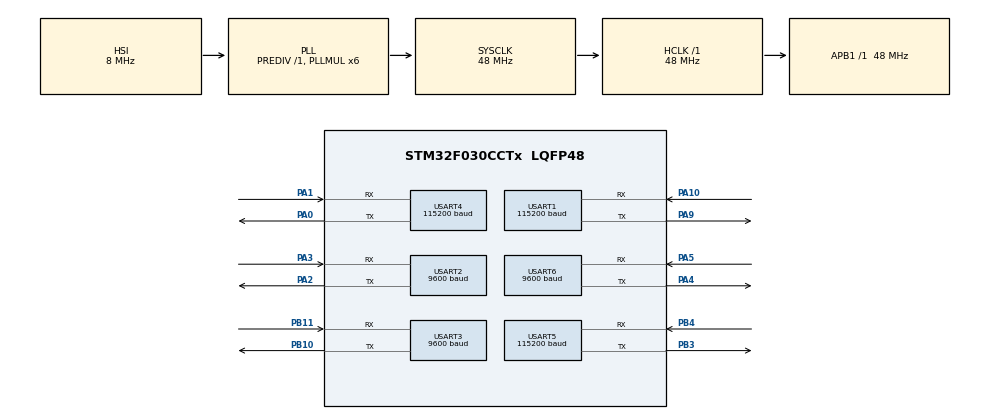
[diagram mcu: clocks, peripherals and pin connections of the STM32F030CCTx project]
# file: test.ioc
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Dma.Request0=USART1_RX
Dma.Request1=USART5_RX
Dma.Request2=USART4_RX
Dma.USART1_RX.0.Direction=DMA_PERIPH_TO_MEMORY
Dma.USART1_RX.0.Instance=DMA1_Channel1
Dma.USART1_RX.0.MemDataAlignment=DMA_MDATAALIGN_BYTE
Dma.USART1_RX.0.MemInc=DMA_MINC_ENABLE
Dma.USART1_RX.0.Mode=DMA_NORMAL
Dma.USART1_RX.0.PeriphDataAlignment=DMA_PDATAALIGN_BYTE
Dma.USART1_RX.0.PeriphInc=DMA_PINC_DISABLE
Dma.USART1_RX.0.Priority=DMA_PRIORITY_MEDIUM
Dma.USART4_RX.2.Direction=DMA_PERIPH_TO_MEMORY
Dma.USART4_RX.2.Instance=DMA1_Channel5
Dma.USART4_RX.2.MemDataAlignment=DMA_MDATAALIGN_BYTE
Dma.USART4_RX.2.MemInc=DMA_MINC_ENABLE
Dma.USART4_RX.2.Mode=DMA_NORMAL
Dma.USART4_RX.2.PeriphDataAlignment=DMA_PDATAALIGN_BYTE
Dma.USART4_RX.2.PeriphInc=DMA_PINC_DISABLE
Dma.USART4_RX.2.Priority=DMA_PRIORITY_HIGH
Dma.USART5_RX.1.Direction=DMA_PERIPH_TO_MEMORY
Dma.USART5_RX.1.Instance=DMA1_Channel3
Dma.USART5_RX.1.MemDataAlignment=DMA_MDATAALIGN_BYTE
Dma.USART5_RX.1.MemInc=DMA_MINC_ENABLE
Dma.USART5_RX.1.Mode=DMA_NORMAL
Dma.USART5_RX.1.PeriphDataAlignment=DMA_PDATAALIGN_BYTE
Dma.USART5_RX.1.PeriphInc=DMA_PINC_DISABLE
Dma.USART5_RX.1.Priority=DMA_PRIORITY_MEDIUM
Mcu.Family=STM32F0
Mcu.Name=STM32F030CCTx
Mcu.Package=LQFP48
NVIC.DMA1_Channel1_IRQn=true\:0\:0\:false\:false\:true\:false\:true\:true
NVIC.DMA1_Channel2_3_IRQn=true\:0\:0\:false\:false\:true\:false\:true\:true
NVIC.DMA1_Channel4_5_IRQn=true\:0\:0\:false\:false\:true\:false\:true\:true
NVIC.USART1_IRQn=true\:0\:0\:false\:false\:true\:true\:true\:true
NVIC.USART3_6_IRQn=true\:0\:0\:false\:false\:true\:true\:true\:true
PA0.Mode=Asynchronous
PA0.Signal=USART4_TX
PA1.Mode=Asynchronous
PA1.Signal=USART4_RX
PA10.Mode=Asynchronous
PA10.Signal=USART1_RX
PA2.Mode=Asynchronous
PA2.Signal=USART2_TX
PA3.Mode=Asynchronous
PA3.Signal=USART2_RX
PA4.Mode=Asynchronous
PA4.Signal=USART6_TX
PA5.Mode=Asynchronous
PA5.Signal=USART6_RX
PA9.Mode=Asynchronous
PA9.Signal=USART1_TX
PB10.Mode=Asynchronous
PB10.Signal=USART3_TX
PB11.Mode=Asynchronous
PB11.Signal=USART3_RX
PB3.Mode=Asynchronous
PB3.Signal=USART5_TX
PB4.Mode=Asynchronous
PB4.Signal=USART5_RX
PF0-OSC_IN.Mode=HSE-External-Oscillator
PF0-OSC_IN.Signal=RCC_OSC_IN
PF1-OSC_OUT.Mode=HSE-External-Oscillator
PF1-OSC_OUT.Signal=RCC_OSC_OUT
ProjectManager.HeapSize=0x200
ProjectManager.StackSize=0x400
ProjectManager.TargetToolchain=STM32CubeIDE
RCC.AHBFreq_Value=48000000
RCC.APB1Freq_Value=48000000
RCC.APB1TimFreq_Value=48000000
RCC.HCLKFreq_Value=48000000
RCC.PLLMUL=RCC_PLL_MUL6
RCC.SYSCLKFreq_VALUE=48000000
RCC.SYSCLKSource=RCC_SYSCLKSOURCE_PLLCLK
USART1.BaudRate=115200
USART1.VirtualMode-Asynchronous=VM_ASYNC
USART2.BaudRate=9600
USART2.VirtualMode-Asynchronous=VM_ASYNC
USART3.BaudRate=9600
USART3.VirtualMode-Asynchronous=VM_ASYNC
USART4.BaudRate=115200
USART4.VirtualMode-Asynchronous=VM_ASYNC
USART5.BaudRate=115200
USART5.VirtualMode-Asynchronous=VM_ASYNC
USART6.BaudRate=9600
USART6.VirtualMode=VM_ASYNC
board=custom

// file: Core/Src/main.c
/* USER CODE BEGIN Header */
/**
  ******************************************************************************
  * @file           : main.c
  * @brief          : Main program body
  ******************************************************************************
  * @attention
  *
  * Copyright (c) 2025 STMicroelectronics.
  * All rights reserved.
  *
  * This software is licensed under terms that can be found in the LICENSE file
  * in the root directory of this software component.
  * If no LICENSE file comes with this software, it is provided AS-IS.
  *
  ******************************************************************************
  */
/* USER CODE END Header */
#include "main.h"
#include "string.h"

/* USER CODE BEGIN PD */
#define MAX_PACKETS     30
#define MAX_PACKET_SIZE 200
/* USER CODE END PD */

UART_HandleTypeDef huart1;
UART_HandleTypeDef huart2;
UART_HandleTypeDef huart3;
UART_HandleTypeDef huart4;
UART_HandleTypeDef huart5;
UART_HandleTypeDef huart6;
DMA_HandleTypeDef hdma_usart1_rx;
DMA_HandleTypeDef hdma_usart4_rx;
DMA_HandleTypeDef hdma_usart5_rx;

uint8_t UART1_RxBuffer[100] = {0}; //UART1: HMI
uint8_t UART5_RxBuffer[100] = {0}; //UART5: Robot
uint8_t UART4_RxBuffer[2000] = {0}; //UART4: Laser Controller
uint8_t buffer[1000] = {0};
uint8_t transfer[100] = {0};
uint8_t uart4_packets[MAX_PACKETS][MAX_PACKET_SIZE];  // Store extracted packets
uint16_t uart4_packet_sizes[MAX_PACKETS];      // Store actual sizes
uint8_t prt[10] = {0};
uint8_t p = 0;
uint8_t pno[1] = {0};
uint16_t RxDataLen = 0;
void SystemClock_Config(void);
static void MX_GPIO_Init(void);
static void MX_DMA_Init(void);
static void MX_USART1_UART_Init(void);
static void MX_USART2_UART_Init(void);
static void MX_USART3_UART_Init(void);
static void MX_USART4_UART_Init(void);
static void MX_USART5_UART_Init(void);
static void MX_USART6_UART_Init(void);

int main(void)
{

  /* MCU Configuration--------------------------------------------------------*/

  /* Reset of all peripherals, Initializes the Flash interface and the Systick. */
  HAL_Init();

  /* Configure the system clock */
  SystemClock_Config();

  /* Initialize all configured peripherals */
  MX_GPIO_Init();
  MX_DMA_Init();
  MX_USART1_UART_Init();
  MX_USART2_UART_Init();
  MX_USART3_UART_Init();
  MX_USART4_UART_Init();
  MX_USART5_UART_Init();
  MX_USART6_UART_Init();
  /* USER CODE BEGIN 2 */

  HAL_UARTEx_ReceiveToIdle_DMA(&huart1, UART1_RxBuffer, 100); //Read from HMI
  __HAL_DMA_DISABLE_IT(&hdma_usart1_rx, DMA_IT_HT);
  HAL_UARTEx_ReceiveToIdle_DMA(&huart5, UART5_RxBuffer, 100); //Read from Robot
  __HAL_DMA_DISABLE_IT(&hdma_usart5_rx, DMA_IT_HT);
  HAL_UARTEx_ReceiveToIdle_DMA(&huart4, UART4_RxBuffer, 1000); //Read from Laser Controller
  __HAL_DMA_DISABLE_IT(&hdma_usart4_rx, DMA_IT_HT);
  /* USER CODE END 2 */

  /* Infinite loop */
  while (1)
  {
	  if (buffer[0] != 0 )
	 	  {
	 		  memcpy(transfer, buffer, 100);
	 		  memmove(buffer, &buffer[100], 900);
	 		  memset(&buffer[900], 0, 100);
	 		  pno[0] = prt[0];
	 		  memmove(prt, &prt[1],9);
	 		  HAL_UART_Transmit(&huart4, transfer, RxDataLen, 500);
	 		  //HAL_Delay(500);
	 	  }
    /* USER CODE BEGIN 3 */
  }
  //memset(UART1_RxBuffer, 0, 32);

  /* USER CODE END 3 */
}

void extract_uart4_packets(uint8_t *buf, uint16_t len) {
    int pkt_idx = 0;

    for (int i = 0; i < len - 1 && pkt_idx < MAX_PACKETS; ) {
        // Look for start marker
        if (buf[i] == 0x5A && buf[i + 1] == 0xA5) {
            int start = i;
            int end = -1;

            // Find next 0x5A 0xA5 (start of next packet)
            for (int j = i + 2; j < len - 1; j++) {
                if (buf[j] == 0x5A && buf[j + 1] == 0xA5) {
                    end = j;
                    break;
                }
            }

            if (end == -1) {
                // No more headers → rest is last packet
                end = len;
            }

            int pkt_len = end - start;
            if (pkt_len > 0 && pkt_len <= MAX_PACKET_SIZE) {
                memcpy(uart4_packets[pkt_idx], &buf[start], pkt_len);
                uart4_packet_sizes[pkt_idx] = pkt_len;
                pkt_idx++;
            }

            i = end; // Continue from next header or end
        } else {
            i++; // Not a packet start, scan forward
        }
    }

    // Clear unused sizes
    for (int j = pkt_idx; j < MAX_PACKETS; j++) {
        uart4_packet_sizes[j] = 0;
    }
}

void HAL_UARTEx_RxEventCallback(UART_HandleTypeDef *huart, uint16_t Size)
{
	if (huart->Instance == USART1)
	{
		RxDataLen = Size;
		uint8_t i;
		p = 1;
		//HAL_UART_Transmit(&huart4, UART1_RxBuffer, RxDataLen, 500);
		for (i = 0; i<10; i++)
		{
			if (buffer[i*100] == 0) {
				memcpy(&buffer[i*100], UART1_RxBuffer, 100);
				//break;
			}
			if (prt[i] == 0){
				prt[i] = p;
				break;
			}
		}
		HAL_UARTEx_ReceiveToIdle_DMA(&huart1, UART1_RxBuffer, 100);
		__HAL_DMA_DISABLE_IT(&hdma_usart1_rx, DMA_IT_HT);
	}

	else if (huart->Instance == USART5)
	{
		RxDataLen = Size;
		uint8_t i;
		p = 5;
		//HAL_UART_Transmit(&huart4, rx5_data, RxDataLen, 100);
		for (i = 0; i<10; i++)
		{
			if (buffer[i*100] == 0) {
				memcpy(&buffer[i*100], UART5_RxBuffer, 100);
				//break;
			}
			if (prt[i] == 0){
				prt[i] = p;
				break;
			}
		}
		HAL_UARTEx_ReceiveToIdle_DMA(&huart5, UART5_RxBuffer, 100);
		__HAL_DMA_DISABLE_IT(&hdma_usart5_rx, DMA_IT_HT);
	}

	else if (huart->Instance == USART4)
	{
		RxDataLen = Size;
		extract_uart4_packets(UART4_RxBuffer, Size);
		for (int i = 0; i < MAX_PACKETS && uart4_packet_sizes[i] > 0; i++)
		{
			if (pno[0] == 1){
				HAL_UART_Transmit(&huart1, uart4_packets[i], uart4_packet_sizes[i], 100);
			}
			else if (pno[0] == 5){
				HAL_UART_Transmit(&huart5, uart4_packets[i], uart4_packet_sizes[i], 100);
			}
			else if (pno[0] == 0){
				HAL_UART_Transmit(&huart5, uart4_packets[i], uart4_packet_sizes[i], 100);
			}
		}
		HAL_UARTEx_ReceiveToIdle_DMA(&huart4, UART4_RxBuffer, 1000);
		__HAL_DMA_DISABLE_IT(&hdma_usart4_rx, DMA_IT_HT);
	}
}

void SystemClock_Config(void)
{
  RCC_OscInitTypeDef RCC_OscInitStruct = {0};
  RCC_ClkInitTypeDef RCC_ClkInitStruct = {0};
  RCC_PeriphCLKInitTypeDef PeriphClkInit = {0};

  /** Initializes the RCC Oscillators according to the specified parameters
  * in the RCC_OscInitTypeDef structure.
  */
  RCC_OscInitStruct.OscillatorType = RCC_OSCILLATORTYPE_HSI;
  RCC_OscInitStruct.HSIState = RCC_HSI_ON;
  RCC_OscInitStruct.HSICalibrationValue = RCC_HSICALIBRATION_DEFAULT;
  RCC_OscInitStruct.PLL.PLLState = RCC_PLL_ON;
  RCC_OscInitStruct.PLL.PLLSource = RCC_PLLSOURCE_HSI;
  RCC_OscInitStruct.PLL.PLLMUL = RCC_PLL_MUL6;
  RCC_OscInitStruct.PLL.PREDIV = RCC_PREDIV_DIV1;
  if (HAL_RCC_OscConfig(&RCC_OscInitStruct) != HAL_OK)
  {
    Error_Handler();
  }

  /** Initializes the CPU, AHB and APB buses clocks
  */
  RCC_ClkInitStruct.ClockType = RCC_CLOCKTYPE_HCLK|RCC_CLOCKTYPE_SYSCLK
                              |RCC_CLOCKTYPE_PCLK1;
  RCC_ClkInitStruct.SYSCLKSource = RCC_SYSCLKSOURCE_PLLCLK;
  RCC_ClkInitStruct.AHBCLKDivider = RCC_SYSCLK_DIV1;
  RCC_ClkInitStruct.APB1CLKDivider = RCC_HCLK_DIV1;

  if (HAL_RCC_ClockConfig(&RCC_ClkInitStruct, FLASH_LATENCY_1) != HAL_OK)
  {
    Error_Handler();
  }
  PeriphClkInit.PeriphClockSelection = RCC_PERIPHCLK_USART1;
  PeriphClkInit.Usart1ClockSelection = RCC_USART1CLKSOURCE_PCLK1;
  if (HAL_RCCEx_PeriphCLKConfig(&PeriphClkInit) != HAL_OK)
  {
    Error_Handler();
  }
}

static void MX_USART1_UART_Init(void)
{

  huart1.Instance = USART1;
  huart1.Init.BaudRate = 115200;
  huart1.Init.WordLength = UART_WORDLENGTH_8B;
  huart1.Init.StopBits = UART_STOPBITS_1;
  huart1.Init.Parity = UART_PARITY_NONE;
  huart1.Init.Mode = UART_MODE_TX_RX;
  huart1.Init.HwFlowCtl = UART_HWCONTROL_NONE;
  huart1.Init.OverSampling = UART_OVERSAMPLING_16;
  huart1.Init.OneBitSampling = UART_ONE_BIT_SAMPLE_DISABLE;
  huart1.AdvancedInit.AdvFeatureInit = UART_ADVFEATURE_NO_INIT;
  if (HAL_UART_Init(&huart1) != HAL_OK)
  {
    Error_Handler();
  }

}

static void MX_USART2_UART_Init(void)
{

  huart2.Instance = USART2;
  huart2.Init.BaudRate = 9600;
  huart2.Init.WordLength = UART_WORDLENGTH_8B;
  huart2.Init.StopBits = UART_STOPBITS_1;
  huart2.Init.Parity = UART_PARITY_NONE;
  huart2.Init.Mode = UART_MODE_TX_RX;
  huart2.Init.HwFlowCtl = UART_HWCONTROL_NONE;
  huart2.Init.OverSampling = UART_OVERSAMPLING_16;
  huart2.Init.OneBitSampling = UART_ONE_BIT_SAMPLE_DISABLE;
  huart2.AdvancedInit.AdvFeatureInit = UART_ADVFEATURE_NO_INIT;
  if (HAL_UART_Init(&huart2) != HAL_OK)
  {
    Error_Handler();
  }

}

static void MX_USART3_UART_Init(void)
{

  huart3.Instance = USART3;
  huart3.Init.BaudRate = 9600;
  huart3.Init.WordLength = UART_WORDLENGTH_8B;
  huart3.Init.StopBits = UART_STOPBITS_1;
  huart3.Init.Parity = UART_PARITY_NONE;
  huart3.Init.Mode = UART_MODE_TX_RX;
  huart3.Init.HwFlowCtl = UART_HWCONTROL_NONE;
  huart3.Init.OverSampling = UART_OVERSAMPLING_16;
  huart3.Init.OneBitSampling = UART_ONE_BIT_SAMPLE_DISABLE;
  huart3.AdvancedInit.AdvFeatureInit = UART_ADVFEATURE_NO_INIT;
  if (HAL_UART_Init(&huart3) != HAL_OK)
  {
    Error_Handler();
  }

}

static void MX_USART4_UART_Init(void)
{

  huart4.Instance = USART4;
  huart4.Init.BaudRate = 115200;
  huart4.Init.WordLength = UART_WORDLENGTH_8B;
  huart4.Init.StopBits = UART_STOPBITS_1;
  huart4.Init.Parity = UART_PARITY_NONE;
  huart4.Init.Mode = UART_MODE_TX_RX;
  huart4.Init.HwFlowCtl = UART_HWCONTROL_NONE;
  huart4.Init.OverSampling = UART_OVERSAMPLING_16;
  huart4.Init.OneBitSampling = UART_ONE_BIT_SAMPLE_DISABLE;
  huart4.AdvancedInit.AdvFeatureInit = UART_ADVFEATURE_NO_INIT;
  if (HAL_UART_Init(&huart4) != HAL_OK)
  {
    Error_Handler();
  }

}

static void MX_USART5_UART_Init(void)
{

  huart5.Instance = USART5;
  huart5.Init.BaudRate = 115200;
  huart5.Init.WordLength = UART_WORDLENGTH_8B;
  huart5.Init.StopBits = UART_STOPBITS_1;
  huart5.Init.Parity = UART_PARITY_NONE;
  huart5.Init.Mode = UART_MODE_TX_RX;
  huart5.Init.HwFlowCtl = UART_HWCONTROL_NONE;
  huart5.Init.OverSampling = UART_OVERSAMPLING_16;
  huart5.Init.OneBitSampling = UART_ONE_BIT_SAMPLE_DISABLE;
  huart5.AdvancedInit.AdvFeatureInit = UART_ADVFEATURE_NO_INIT;
  if (HAL_UART_Init(&huart5) != HAL_OK)
  {
    Error_Handler();
  }

}

static void MX_USART6_UART_Init(void)
{

  huart6.Instance = USART6;
  huart6.Init.BaudRate = 9600;
  huart6.Init.WordLength = UART_WORDLENGTH_8B;
  huart6.Init.StopBits = UART_STOPBITS_1;
  huart6.Init.Parity = UART_PARITY_NONE;
  huart6.Init.Mode = UART_MODE_TX_RX;
  huart6.Init.HwFlowCtl = UART_HWCONTROL_NONE;
  huart6.Init.OverSampling = UART_OVERSAMPLING_16;
  huart6.Init.OneBitSampling = UART_ONE_BIT_SAMPLE_DISABLE;
  huart6.AdvancedInit.AdvFeatureInit = UART_ADVFEATURE_NO_INIT;
  if (HAL_UART_Init(&huart6) != HAL_OK)
  {
    Error_Handler();
  }

}

static void MX_DMA_Init(void)
{

  /* DMA controller clock enable */
  __HAL_RCC_DMA1_CLK_ENABLE();

  /* DMA interrupt init */
  /* DMA1_Channel1_IRQn interrupt configuration */
  HAL_NVIC_SetPriority(DMA1_Channel1_IRQn, 0, 0);
  HAL_NVIC_EnableIRQ(DMA1_Channel1_IRQn);
  /* DMA1_Channel2_3_IRQn interrupt configuration */
  HAL_NVIC_SetPriority(DMA1_Channel2_3_IRQn, 0, 0);
  HAL_NVIC_EnableIRQ(DMA1_Channel2_3_IRQn);
  /* DMA1_Channel4_5_IRQn interrupt configuration */
  HAL_NVIC_SetPriority(DMA1_Channel4_5_IRQn, 0, 0);
  HAL_NVIC_EnableIRQ(DMA1_Channel4_5_IRQn);

}

static void MX_GPIO_Init(void)
{

  /* GPIO Ports Clock Enable */
  __HAL_RCC_GPIOF_CLK_ENABLE();
  __HAL_RCC_GPIOA_CLK_ENABLE();
  __HAL_RCC_GPIOB_CLK_ENABLE();

}

void Error_Handler(void)
{
  __disable_irq();
  while (1)
  {
  }
}
